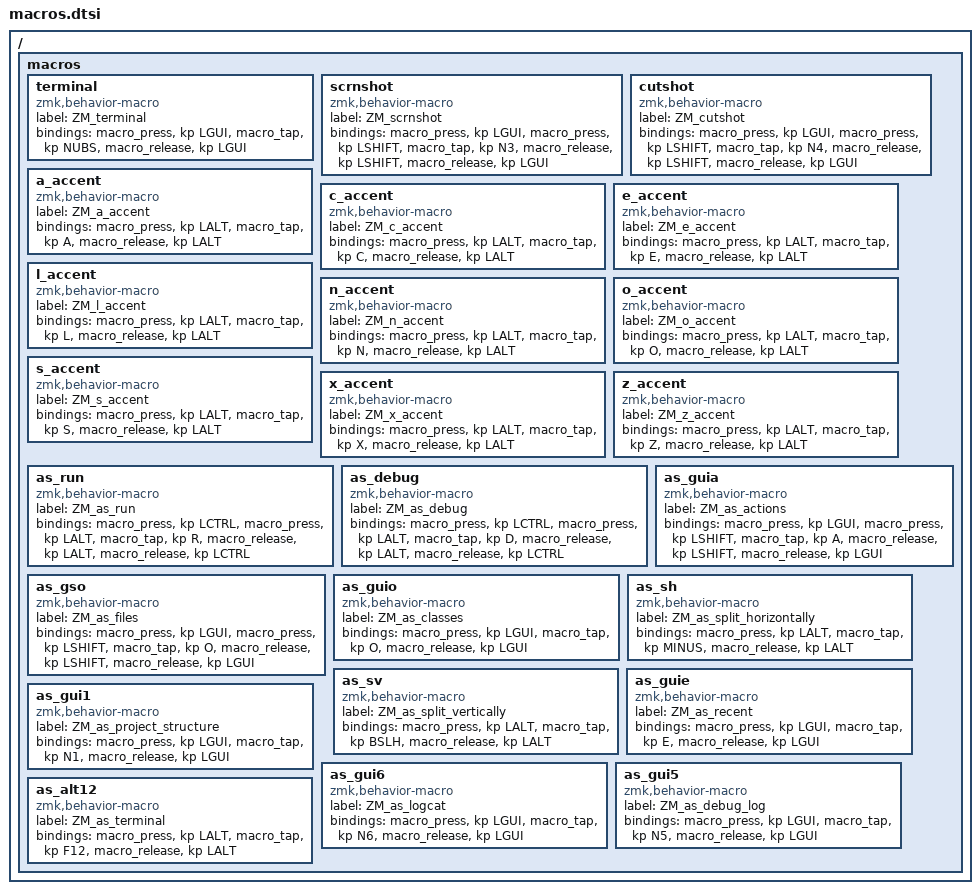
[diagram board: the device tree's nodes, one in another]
/ {
    macros {
        // SYSTEM
        terminal: terminal {
            label = "ZM_terminal";
            compatible = "zmk,behavior-macro";
            #binding-cells = <0>;
            bindings
                = <&macro_press &kp LGUI>
                , <&macro_tap &kp NUBS>
                , <&macro_release &kp LGUI>
                ;
        };
        scrnshot: scrnshot {
            label = "ZM_scrnshot";
            compatible = "zmk,behavior-macro";
            #binding-cells = <0>;
            bindings
                = <&macro_press &kp LGUI>
                , <&macro_press &kp LSHIFT>
                , <&macro_tap &kp N3>
                , <&macro_release &kp LSHIFT>
                , <&macro_release &kp LGUI>
                ;
        };
        cutshot: cutshot {
            label = "ZM_cutshot";
            compatible = "zmk,behavior-macro";
            #binding-cells = <0>;
            bindings
                = <&macro_press &kp LGUI>
                , <&macro_press &kp LSHIFT>
                , <&macro_tap &kp N4>
                , <&macro_release &kp LSHIFT>
                , <&macro_release &kp LGUI>
                ;
        };
        // ACCENTS
        a_accent: a_accent {
            label = "ZM_a_accent";
            compatible = "zmk,behavior-macro";
            #binding-cells = <0>;
            bindings
                = <&macro_press &kp LALT>
                , <&macro_tap &kp A>
                , <&macro_release &kp LALT>
                ;
        };
        c_accent: c_accent {
            label = "ZM_c_accent";
            compatible = "zmk,behavior-macro";
            #binding-cells = <0>;
            bindings
                = <&macro_press &kp LALT>
                , <&macro_tap &kp C>
                , <&macro_release &kp LALT>
                ;
        };
        e_accent: e_accent {
            label = "ZM_e_accent";
            compatible = "zmk,behavior-macro";
            #binding-cells = <0>;
            bindings
                = <&macro_press &kp LALT>
                , <&macro_tap &kp E>
                , <&macro_release &kp LALT>
                ;
        };
        l_accent: l_accent {
            label = "ZM_l_accent";
            compatible = "zmk,behavior-macro";
            #binding-cells = <0>;
            bindings
                = <&macro_press &kp LALT>
                , <&macro_tap &kp L>
                , <&macro_release &kp LALT>
                ;
        };
        n_accent: n_accent {
            label = "ZM_n_accent";
            compatible = "zmk,behavior-macro";
            #binding-cells = <0>;
            bindings
                = <&macro_press &kp LALT>
                , <&macro_tap &kp N>
                , <&macro_release &kp LALT>
                ;
        };
        o_accent: o_accent {
            label = "ZM_o_accent";
            compatible = "zmk,behavior-macro";
            #binding-cells = <0>;
            bindings
                = <&macro_press &kp LALT>
                , <&macro_tap &kp O>
                , <&macro_release &kp LALT>
                ;
        };
        s_accent: s_accent {
            label = "ZM_s_accent";
            compatible = "zmk,behavior-macro";
            #binding-cells = <0>;
            bindings
                = <&macro_press &kp LALT>
                , <&macro_tap &kp S>
                , <&macro_release &kp LALT>
                ;
        };
        x_accent: x_accent {
            label = "ZM_x_accent";
            compatible = "zmk,behavior-macro";
            #binding-cells = <0>;
            bindings
                = <&macro_press &kp LALT>
                , <&macro_tap &kp X>
                , <&macro_release &kp LALT>
                ;
        };
        z_accent: z_accent {
            label = "ZM_z_accent";
            compatible = "zmk,behavior-macro";
            #binding-cells = <0>;
            bindings
                = <&macro_press &kp LALT>
                , <&macro_tap &kp Z>
                , <&macro_release &kp LALT>
                ;
        };
        // ANDROID STUDIO
        as_run: as_run {
            label = "ZM_as_run";
            compatible = "zmk,behavior-macro";
            #binding-cells = <0>;
            bindings
                = <&macro_press &kp LCTRL>
                , <&macro_press &kp LALT>
                , <&macro_tap &kp R>
                , <&macro_release &kp LALT>
                , <&macro_release &kp LCTRL>
                ;
        };
        as_debug: as_debug {
            label = "ZM_as_debug";
            compatible = "zmk,behavior-macro";
            #binding-cells = <0>;
            bindings
                = <&macro_press &kp LCTRL>
                , <&macro_press &kp LALT>
                , <&macro_tap &kp D>
                , <&macro_release &kp LALT>
                , <&macro_release &kp LCTRL>
                ;
        };
        as_guia: as_guia {
            label = "ZM_as_actions";
            compatible = "zmk,behavior-macro";
            #binding-cells = <0>;
            bindings
                = <&macro_press &kp LGUI>
                , <&macro_press &kp LSHIFT>
                , <&macro_tap &kp A>
                , <&macro_release &kp LSHIFT>
                , <&macro_release &kp LGUI>
                ;
        };
        as_gso: as_gso {
            label = "ZM_as_files";
            compatible = "zmk,behavior-macro";
            #binding-cells = <0>;
            bindings
                = <&macro_press &kp LGUI>
                , <&macro_press &kp LSHIFT>
                , <&macro_tap &kp O>
                , <&macro_release &kp LSHIFT>
                , <&macro_release &kp LGUI>
                ;
        };
        as_guio: as_guio {
            label = "ZM_as_classes";
            compatible = "zmk,behavior-macro";
            #binding-cells = <0>;
            bindings
                = <&macro_press &kp LGUI>
                , <&macro_tap &kp O>
                , <&macro_release &kp LGUI>
                ;
        };
        as_sh: as_sh {
            label = "ZM_as_split_horizontally";
            compatible = "zmk,behavior-macro";
            #binding-cells = <0>;
            bindings
                = <&macro_press &kp LALT>
                , <&macro_tap &kp MINUS>
                , <&macro_release &kp LALT>
                ;
        };
        as_sv: as_sv {
            label = "ZM_as_split_vertically";
            compatible = "zmk,behavior-macro";
            #binding-cells = <0>;
            bindings
                = <&macro_press &kp LALT>
                , <&macro_tap &kp BSLH>
                , <&macro_release &kp LALT>
                ;
        };
        as_guie: as_guie {
            label = "ZM_as_recent";
            compatible = "zmk,behavior-macro";
            #binding-cells = <0>;
            bindings
                = <&macro_press &kp LGUI>
                , <&macro_tap &kp E>
                , <&macro_release &kp LGUI>
                ;
        };
        as_gui1: as_gui1 {
            label = "ZM_as_project_structure";
            compatible = "zmk,behavior-macro";
            #binding-cells = <0>;
            bindings
                = <&macro_press &kp LGUI>
                , <&macro_tap &kp N1>
                , <&macro_release &kp LGUI>
                ;
        };
        as_gui6: as_gui6 {
            label = "ZM_as_logcat";
            compatible = "zmk,behavior-macro";
            #binding-cells = <0>;
            bindings
                = <&macro_press &kp LGUI>
                , <&macro_tap &kp N6>
                , <&macro_release &kp LGUI>
                ;
        };
        as_gui5: as_gui5 {
            label = "ZM_as_debug_log";
            compatible = "zmk,behavior-macro";
            #binding-cells = <0>;
            bindings
                = <&macro_press &kp LGUI>
                , <&macro_tap &kp N5>
                , <&macro_release &kp LGUI>
                ;
        };
        as_alt12: as_alt12 {
            label = "ZM_as_terminal";
            compatible = "zmk,behavior-macro";
            #binding-cells = <0>;
            bindings
                = <&macro_press &kp LALT>
                , <&macro_tap &kp F12>
                , <&macro_release &kp LALT>
                ;
        };
    };
};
